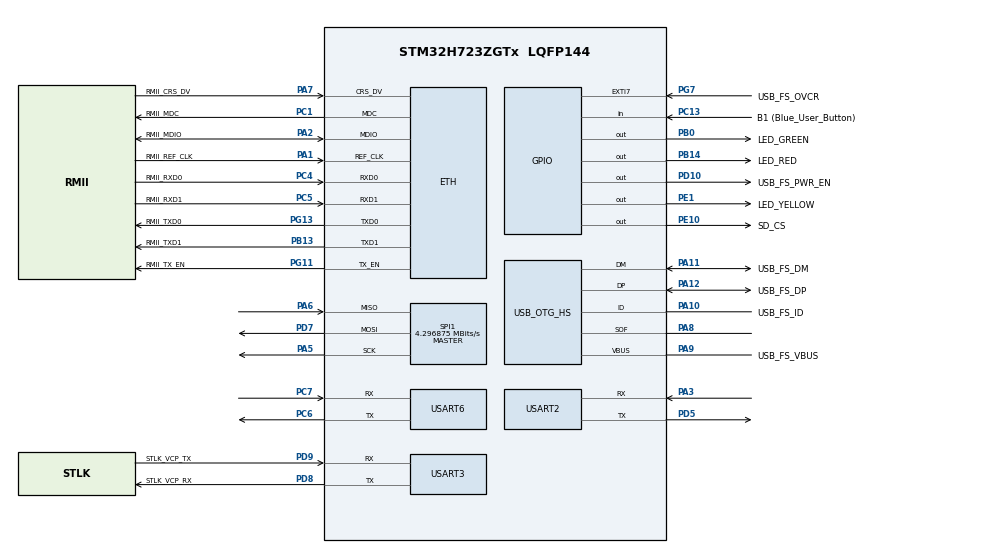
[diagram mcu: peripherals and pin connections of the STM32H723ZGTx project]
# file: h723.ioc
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Dma.Request0=USART3_RX
Dma.Request1=USART2_RX
Dma.USART2_RX.1.Direction=DMA_PERIPH_TO_MEMORY
Dma.USART2_RX.1.EventEnable=DISABLE
Dma.USART2_RX.1.FIFOMode=DMA_FIFOMODE_DISABLE
Dma.USART2_RX.1.Instance=DMA1_Stream1
Dma.USART2_RX.1.MemDataAlignment=DMA_MDATAALIGN_BYTE
Dma.USART2_RX.1.MemInc=DMA_MINC_ENABLE
Dma.USART2_RX.1.Mode=DMA_CIRCULAR
Dma.USART2_RX.1.PeriphDataAlignment=DMA_PDATAALIGN_BYTE
Dma.USART2_RX.1.PeriphInc=DMA_PINC_DISABLE
Dma.USART2_RX.1.Polarity=HAL_DMAMUX_REQ_GEN_RISING
Dma.USART2_RX.1.Priority=DMA_PRIORITY_LOW
Dma.USART2_RX.1.RequestNumber=1
Dma.USART2_RX.1.SignalID=NONE
Dma.USART2_RX.1.SyncEnable=DISABLE
Dma.USART2_RX.1.SyncPolarity=HAL_DMAMUX_SYNC_NO_EVENT
Dma.USART2_RX.1.SyncRequestNumber=1
Dma.USART2_RX.1.SyncSignalID=NONE
Dma.USART3_RX.0.Direction=DMA_PERIPH_TO_MEMORY
Dma.USART3_RX.0.EventEnable=DISABLE
Dma.USART3_RX.0.FIFOMode=DMA_FIFOMODE_DISABLE
Dma.USART3_RX.0.Instance=DMA1_Stream0
Dma.USART3_RX.0.MemDataAlignment=DMA_MDATAALIGN_BYTE
Dma.USART3_RX.0.MemInc=DMA_MINC_ENABLE
Dma.USART3_RX.0.Mode=DMA_CIRCULAR
Dma.USART3_RX.0.PeriphDataAlignment=DMA_PDATAALIGN_BYTE
Dma.USART3_RX.0.PeriphInc=DMA_PINC_DISABLE
Dma.USART3_RX.0.Polarity=HAL_DMAMUX_REQ_GEN_RISING
Dma.USART3_RX.0.Priority=DMA_PRIORITY_LOW
Dma.USART3_RX.0.RequestNumber=1
Dma.USART3_RX.0.SignalID=NONE
Dma.USART3_RX.0.SyncEnable=DISABLE
Dma.USART3_RX.0.SyncPolarity=HAL_DMAMUX_SYNC_NO_EVENT
Dma.USART3_RX.0.SyncRequestNumber=1
Dma.USART3_RX.0.SyncSignalID=NONE
ETH.MediaInterface=HAL_ETH_RMII_MODE
FATFS._MAX_SS=4096
FATFS._USE_LFN=1
Mcu.Family=STM32H7
Mcu.Name=STM32H723ZGTx
Mcu.Package=LQFP144
NVIC.DMA1_Stream0_IRQn=true\:0\:0\:false\:false\:true\:false\:true\:true
NVIC.DMA1_Stream1_IRQn=true\:0\:0\:false\:false\:true\:false\:true\:true
NVIC.PriorityGroup=NVIC_PRIORITYGROUP_4
NVIC.TIM1_UP_IRQn=true\:15\:0\:false\:false\:true\:false\:true\:true
NVIC.TimeBase=TIM1_UP_IRQn
NVIC.TimeBaseIP=TIM1
NVIC.USART2_IRQn=true\:5\:0\:true\:false\:true\:true\:true\:true
NVIC.USART3_IRQn=true\:5\:0\:true\:false\:true\:true\:true\:true
NVIC.USART6_IRQn=true\:5\:0\:true\:false\:true\:true\:true\:true
PA1.GPIO_Label=RMII_REF_CLK
PA1.Mode=RMII
PA1.Signal=ETH_REF_CLK
PA10.GPIO_Label=USB_FS_ID
PA10.Mode=OTG/Dual-Role-Device-FS
PA10.Signal=USB_OTG_HS_ID
PA11.GPIO_Label=USB_FS_DM
PA11.Mode=OTG/Dual-Role-Device-FS
PA11.Signal=USB_OTG_HS_DM
PA12.GPIO_Label=USB_FS_DP
PA12.Mode=OTG/Dual-Role-Device-FS
PA12.Signal=USB_OTG_HS_DP
PA13(JTMS/SWDIO).GPIO_Label=SWDIO
PA13(JTMS/SWDIO).Mode=Trace_Asynchronous_SW
PA13(JTMS/SWDIO).Signal=DEBUG_JTMS-SWDIO
PA14(JTCK/SWCLK).GPIO_Label=SWCLK
PA14(JTCK/SWCLK).Mode=Trace_Asynchronous_SW
PA14(JTCK/SWCLK).Signal=DEBUG_JTCK-SWCLK
PA2.GPIO_Label=RMII_MDIO
PA2.Mode=RMII
PA2.Signal=ETH_MDIO
PA3.Mode=Asynchronous
PA3.Signal=USART2_RX
PA5.Mode=Full_Duplex_Master
PA5.Signal=SPI1_SCK
PA6.Mode=Full_Duplex_Master
PA6.Signal=SPI1_MISO
PA7.GPIO_Label=RMII_CRS_DV
PA7.Mode=RMII
PA7.Signal=ETH_CRS_DV
PA8.Mode=Activate_SOF_FS
PA8.Signal=USB_OTG_HS_SOF
PA9.GPIO_Label=USB_FS_VBUS
PA9.Mode=Activate_VBUS_FS
PA9.Signal=USB_OTG_HS_VBUS
PB0.GPIO_Label=LED_GREEN
PB0.Signal=GPIO_Output
PB13.GPIO_Label=RMII_TXD1
PB13.Mode=RMII
PB13.Signal=ETH_TXD1
PB14.GPIO_Label=LED_RED
PB14.Signal=GPIO_Output
PB3(JTDO/TRACESWO).GPIO_Label=SWO
PB3(JTDO/TRACESWO).Mode=Trace_Asynchronous_SW
PB3(JTDO/TRACESWO).Signal=DEBUG_JTDO-SWO
PC1.GPIO_Label=RMII_MDC
PC1.Mode=RMII
PC1.Signal=ETH_MDC
PC13.GPIO_Label=B1 (Blue_User_Button)
PC13.Signal=GPIO_Input
PC14-OSC32_IN.Mode=LSE-External-Oscillator
PC14-OSC32_IN.Signal=RCC_OSC32_IN
PC15-OSC32_OUT.Mode=LSE-External-Oscillator
PC15-OSC32_OUT.Signal=RCC_OSC32_OUT
PC4.GPIO_Label=RMII_RXD0
PC4.Mode=RMII
PC4.Signal=ETH_RXD0
PC5.GPIO_Label=RMII_RXD1
PC5.Mode=RMII
PC5.Signal=ETH_RXD1
PC6.Mode=Asynchronous
PC6.Signal=USART6_TX
PC7.Mode=Asynchronous
PC7.Signal=USART6_RX
PD10.GPIO_Label=USB_FS_PWR_EN
PD10.Signal=GPIO_Output
PD5.Mode=Asynchronous
PD5.Signal=USART2_TX
PD7.Mode=Full_Duplex_Master
PD7.Signal=SPI1_MOSI
PD8.GPIO_Label=STLK_VCP_RX
PD8.Mode=Asynchronous
PD8.Signal=USART3_TX
PD9.GPIO_Label=STLK_VCP_TX
PD9.Mode=Asynchronous
PD9.Signal=USART3_RX
PE1.GPIO_Label=LED_YELLOW
PE1.Signal=GPIO_Output
PE10.GPIO_Label=SD_CS
PE10.PinState=GPIO_PIN_SET
PE10.Signal=GPIO_Output
PG11.GPIO_Label=RMII_TX_EN
PG11.Mode=RMII
PG11.Signal=ETH_TX_EN
PG13.GPIO_Label=RMII_TXD0
PG13.Mode=RMII
PG13.Signal=ETH_TXD0
PG7.GPIO_Label=USB_FS_OVCR
PG7.Signal=GPXTI7
PH0-OSC_IN.GPIO_Label=MCO
PH0-OSC_IN.Mode=HSE-External-Clock-Source
PH0-OSC_IN.Signal=RCC_OSC_IN
PH1-OSC_OUT.Signal=RCC_OSC_OUT
ProjectManager.HeapSize=0x200
ProjectManager.StackSize=0x400
ProjectManager.TargetToolchain=Makefile
RCC.ADCFreq_Value=76000000
RCC.APB1Freq_Value=137500000
RCC.APB2Freq_Value=137500000
RCC.APB3Freq_Value=137500000
RCC.APB4Freq_Value=137500000
RCC.CortexFreq_Value=550000000
RCC.D1PPRE=RCC_APB3_DIV2
RCC.D2PPRE1=RCC_APB1_DIV2
RCC.D2PPRE2=RCC_APB2_DIV2
RCC.D3PPRE=RCC_APB4_DIV2
RCC.DIVM1=4
RCC.DIVM2=1
RCC.DIVN1=275
RCC.DIVN2=19
RCC.DIVP1=1
RCC.DIVQ1=4
RCC.HCLKFreq_Value=275000000
RCC.HPRE=RCC_HCLK_DIV2
RCC.HSE_VALUE=8000000
RCC.PLLFRACN=0
RCC.PLLSourceVirtual=RCC_PLLSOURCE_HSE
RCC.SYSCLKFreq_VALUE=550000000
RCC.SYSCLKSource=RCC_SYSCLKSOURCE_PLLCLK
RCC.USBCLockSelection=RCC_USBCLKSOURCE_HSI48
RCC.USBFreq_Value=48000000
SPI1.BaudRatePrescaler=SPI_BAUDRATEPRESCALER_32
SPI1.CalculateBaudRate=4.296875 MBits/s
SPI1.DataSize=SPI_DATASIZE_8BIT
SPI1.Direction=SPI_DIRECTION_2LINES
SPI1.Mode=SPI_MODE_MASTER
SPI1.VirtualType=VM_MASTER
USART2.VirtualMode-Asynchronous=VM_ASYNC
USART3.VirtualMode-Asynchronous=VM_ASYNC
USART6.VirtualMode-Asynchronous=VM_ASYNC
VP_FATFS_VS_Generic.Mode=User_defined
VP_MEMORYMAP_VS_MEMORYMAP.Mode=CurAppReg
VP_SYS_VS_tim1.Mode=TIM1
board=NUCLEO-H723ZG

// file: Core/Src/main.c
/* USER CODE BEGIN Header */
/**
  ******************************************************************************
  * @file           : main.c
  * @brief          : Main program body
  ******************************************************************************
  * @attention
  *
  * Copyright (c) 2024 STMicroelectronics.
  * All rights reserved.
  *
  * This software is licensed under terms that can be found in the LICENSE file
  * in the root directory of this software component.
  * If no LICENSE file comes with this software, it is provided AS-IS.
  *
  ******************************************************************************
  */
/* USER CODE END Header */
#include "main.h"
#include "string.h"
#include "fatfs.h"

/* USER CODE BEGIN Includes */
#include "port_layer.h"
/* USER CODE END Includes */

#if defined ( __ICCARM__ ) /*!< IAR Compiler */
#pragma location=0x30000000
ETH_DMADescTypeDef  DMARxDscrTab[ETH_RX_DESC_CNT]; /* Ethernet Rx DMA Descriptors */
#pragma location=0x30000080
ETH_DMADescTypeDef  DMATxDscrTab[ETH_TX_DESC_CNT]; /* Ethernet Tx DMA Descriptors */

#elif defined ( __CC_ARM )  /* MDK ARM Compiler */

__attribute__((at(0x30000000))) ETH_DMADescTypeDef  DMARxDscrTab[ETH_RX_DESC_CNT]; /* Ethernet Rx DMA Descriptors */
__attribute__((at(0x30000080))) ETH_DMADescTypeDef  DMATxDscrTab[ETH_TX_DESC_CNT]; /* Ethernet Tx DMA Descriptors */

#elif defined ( __GNUC__ ) /* GNU Compiler */

ETH_DMADescTypeDef DMARxDscrTab[ETH_RX_DESC_CNT] __attribute__((section(".RxDecripSection"))); /* Ethernet Rx DMA Descriptors */
ETH_DMADescTypeDef DMATxDscrTab[ETH_TX_DESC_CNT] __attribute__((section(".TxDecripSection")));   /* Ethernet Tx DMA Descriptors */
#endif

ETH_TxPacketConfig TxConfig;

ETH_HandleTypeDef heth;

SPI_HandleTypeDef hspi1;

UART_HandleTypeDef huart2;
UART_HandleTypeDef huart3;
UART_HandleTypeDef huart6;
DMA_HandleTypeDef hdma_usart2_rx;
DMA_HandleTypeDef hdma_usart3_rx;

void SystemClock_Config(void);
static void MX_GPIO_Init(void);
static void MX_DMA_Init(void);
static void MX_ETH_Init(void);
static void MX_USART3_UART_Init(void);
static void MX_USB_OTG_HS_USB_Init(void);
static void MX_USART2_UART_Init(void);
static void MX_USART6_UART_Init(void);
static void MX_SPI1_Init(void);

int main(void)
{

  /* MCU Configuration--------------------------------------------------------*/

  /* Reset of all peripherals, Initializes the Flash interface and the Systick. */
  HAL_Init();

  /* Configure the system clock */
  SystemClock_Config();

  /* Initialize all configured peripherals */
  MX_GPIO_Init();
  MX_DMA_Init();
  MX_ETH_Init();
  MX_USART3_UART_Init();
  MX_USB_OTG_HS_USB_Init();
  MX_FATFS_Init();
  MX_USART2_UART_Init();
  MX_USART6_UART_Init();
  MX_SPI1_Init();
  /* USER CODE BEGIN 2 */
  //port_init();
  //port_start();
  /* USER CODE END 2 */

  /* Infinite loop */
  while (1)
  {

  }
}

void SystemClock_Config(void)
{
  RCC_OscInitTypeDef RCC_OscInitStruct = {0};
  RCC_ClkInitTypeDef RCC_ClkInitStruct = {0};

  /** Supply configuration update enable
  */
  HAL_PWREx_ConfigSupply(PWR_LDO_SUPPLY);

  /** Configure the main internal regulator output voltage
  */
  __HAL_PWR_VOLTAGESCALING_CONFIG(PWR_REGULATOR_VOLTAGE_SCALE0);

  while(!__HAL_PWR_GET_FLAG(PWR_FLAG_VOSRDY)) {}

  /** Initializes the RCC Oscillators according to the specified parameters
  * in the RCC_OscInitTypeDef structure.
  */
  RCC_OscInitStruct.OscillatorType = RCC_OSCILLATORTYPE_HSI48|RCC_OSCILLATORTYPE_HSE;
  RCC_OscInitStruct.HSEState = RCC_HSE_BYPASS;
  RCC_OscInitStruct.HSI48State = RCC_HSI48_ON;
  RCC_OscInitStruct.PLL.PLLState = RCC_PLL_ON;
  RCC_OscInitStruct.PLL.PLLSource = RCC_PLLSOURCE_HSE;
  RCC_OscInitStruct.PLL.PLLM = 4;
  RCC_OscInitStruct.PLL.PLLN = 275;
  RCC_OscInitStruct.PLL.PLLP = 1;
  RCC_OscInitStruct.PLL.PLLQ = 4;
  RCC_OscInitStruct.PLL.PLLR = 2;
  RCC_OscInitStruct.PLL.PLLRGE = RCC_PLL1VCIRANGE_1;
  RCC_OscInitStruct.PLL.PLLVCOSEL = RCC_PLL1VCOWIDE;
  RCC_OscInitStruct.PLL.PLLFRACN = 0;
  if (HAL_RCC_OscConfig(&RCC_OscInitStruct) != HAL_OK)
  {
    Error_Handler();
  }

  /** Initializes the CPU, AHB and APB buses clocks
  */
  RCC_ClkInitStruct.ClockType = RCC_CLOCKTYPE_HCLK|RCC_CLOCKTYPE_SYSCLK
                              |RCC_CLOCKTYPE_PCLK1|RCC_CLOCKTYPE_PCLK2
                              |RCC_CLOCKTYPE_D3PCLK1|RCC_CLOCKTYPE_D1PCLK1;
  RCC_ClkInitStruct.SYSCLKSource = RCC_SYSCLKSOURCE_PLLCLK;
  RCC_ClkInitStruct.SYSCLKDivider = RCC_SYSCLK_DIV1;
  RCC_ClkInitStruct.AHBCLKDivider = RCC_HCLK_DIV2;
  RCC_ClkInitStruct.APB3CLKDivider = RCC_APB3_DIV2;
  RCC_ClkInitStruct.APB1CLKDivider = RCC_APB1_DIV2;
  RCC_ClkInitStruct.APB2CLKDivider = RCC_APB2_DIV2;
  RCC_ClkInitStruct.APB4CLKDivider = RCC_APB4_DIV2;

  if (HAL_RCC_ClockConfig(&RCC_ClkInitStruct, FLASH_LATENCY_3) != HAL_OK)
  {
    Error_Handler();
  }
}

static void MX_ETH_Init(void)
{

   static uint8_t MACAddr[6];

  heth.Instance = ETH;
  MACAddr[0] = 0x00;
  MACAddr[1] = 0x80;
  MACAddr[2] = 0xE1;
  MACAddr[3] = 0x00;
  MACAddr[4] = 0x00;
  MACAddr[5] = 0x00;
  heth.Init.MACAddr = &MACAddr[0];
  heth.Init.MediaInterface = HAL_ETH_RMII_MODE;
  heth.Init.TxDesc = DMATxDscrTab;
  heth.Init.RxDesc = DMARxDscrTab;
  heth.Init.RxBuffLen = 1524;

  if (HAL_ETH_Init(&heth) != HAL_OK)
  {
    Error_Handler();
  }

  memset(&TxConfig, 0 , sizeof(ETH_TxPacketConfig));
  TxConfig.Attributes = ETH_TX_PACKETS_FEATURES_CSUM | ETH_TX_PACKETS_FEATURES_CRCPAD;
  TxConfig.ChecksumCtrl = ETH_CHECKSUM_IPHDR_PAYLOAD_INSERT_PHDR_CALC;
  TxConfig.CRCPadCtrl = ETH_CRC_PAD_INSERT;

}

static void MX_SPI1_Init(void)
{

  /* SPI1 parameter configuration*/
  hspi1.Instance = SPI1;
  hspi1.Init.Mode = SPI_MODE_MASTER;
  hspi1.Init.Direction = SPI_DIRECTION_2LINES;
  hspi1.Init.DataSize = SPI_DATASIZE_8BIT;
  hspi1.Init.CLKPolarity = SPI_POLARITY_LOW;
  hspi1.Init.CLKPhase = SPI_PHASE_1EDGE;
  hspi1.Init.NSS = SPI_NSS_SOFT;
  hspi1.Init.BaudRatePrescaler = SPI_BAUDRATEPRESCALER_32;
  hspi1.Init.FirstBit = SPI_FIRSTBIT_MSB;
  hspi1.Init.TIMode = SPI_TIMODE_DISABLE;
  hspi1.Init.CRCCalculation = SPI_CRCCALCULATION_DISABLE;
  hspi1.Init.CRCPolynomial = 0x0;
  hspi1.Init.NSSPMode = SPI_NSS_PULSE_ENABLE;
  hspi1.Init.NSSPolarity = SPI_NSS_POLARITY_LOW;
  hspi1.Init.FifoThreshold = SPI_FIFO_THRESHOLD_01DATA;
  hspi1.Init.TxCRCInitializationPattern = SPI_CRC_INITIALIZATION_ALL_ZERO_PATTERN;
  hspi1.Init.RxCRCInitializationPattern = SPI_CRC_INITIALIZATION_ALL_ZERO_PATTERN;
  hspi1.Init.MasterSSIdleness = SPI_MASTER_SS_IDLENESS_00CYCLE;
  hspi1.Init.MasterInterDataIdleness = SPI_MASTER_INTERDATA_IDLENESS_00CYCLE;
  hspi1.Init.MasterReceiverAutoSusp = SPI_MASTER_RX_AUTOSUSP_DISABLE;
  hspi1.Init.MasterKeepIOState = SPI_MASTER_KEEP_IO_STATE_DISABLE;
  hspi1.Init.IOSwap = SPI_IO_SWAP_DISABLE;
  if (HAL_SPI_Init(&hspi1) != HAL_OK)
  {
    Error_Handler();
  }

}

static void MX_USART2_UART_Init(void)
{

  huart2.Instance = USART2;
  huart2.Init.BaudRate = 115200;
  huart2.Init.WordLength = UART_WORDLENGTH_8B;
  huart2.Init.StopBits = UART_STOPBITS_1;
  huart2.Init.Parity = UART_PARITY_NONE;
  huart2.Init.Mode = UART_MODE_TX_RX;
  huart2.Init.HwFlowCtl = UART_HWCONTROL_NONE;
  huart2.Init.OverSampling = UART_OVERSAMPLING_16;
  huart2.Init.OneBitSampling = UART_ONE_BIT_SAMPLE_DISABLE;
  huart2.Init.ClockPrescaler = UART_PRESCALER_DIV1;
  huart2.AdvancedInit.AdvFeatureInit = UART_ADVFEATURE_NO_INIT;
  if (HAL_UART_Init(&huart2) != HAL_OK)
  {
    Error_Handler();
  }
  if (HAL_UARTEx_SetTxFifoThreshold(&huart2, UART_TXFIFO_THRESHOLD_1_8) != HAL_OK)
  {
    Error_Handler();
  }
  if (HAL_UARTEx_SetRxFifoThreshold(&huart2, UART_RXFIFO_THRESHOLD_1_8) != HAL_OK)
  {
    Error_Handler();
  }
  if (HAL_UARTEx_DisableFifoMode(&huart2) != HAL_OK)
  {
    Error_Handler();
  }

}

static void MX_USART3_UART_Init(void)
{

  huart3.Instance = USART3;
  huart3.Init.BaudRate = 115200;
  huart3.Init.WordLength = UART_WORDLENGTH_8B;
  huart3.Init.StopBits = UART_STOPBITS_1;
  huart3.Init.Parity = UART_PARITY_NONE;
  huart3.Init.Mode = UART_MODE_TX_RX;
  huart3.Init.HwFlowCtl = UART_HWCONTROL_NONE;
  huart3.Init.OverSampling = UART_OVERSAMPLING_16;
  huart3.Init.OneBitSampling = UART_ONE_BIT_SAMPLE_DISABLE;
  huart3.Init.ClockPrescaler = UART_PRESCALER_DIV1;
  huart3.AdvancedInit.AdvFeatureInit = UART_ADVFEATURE_NO_INIT;
  if (HAL_UART_Init(&huart3) != HAL_OK)
  {
    Error_Handler();
  }
  if (HAL_UARTEx_SetTxFifoThreshold(&huart3, UART_TXFIFO_THRESHOLD_1_8) != HAL_OK)
  {
    Error_Handler();
  }
  if (HAL_UARTEx_SetRxFifoThreshold(&huart3, UART_RXFIFO_THRESHOLD_1_8) != HAL_OK)
  {
    Error_Handler();
  }
  if (HAL_UARTEx_DisableFifoMode(&huart3) != HAL_OK)
  {
    Error_Handler();
  }

}

static void MX_USART6_UART_Init(void)
{

  huart6.Instance = USART6;
  huart6.Init.BaudRate = 115200;
  huart6.Init.WordLength = UART_WORDLENGTH_8B;
  huart6.Init.StopBits = UART_STOPBITS_1;
  huart6.Init.Parity = UART_PARITY_NONE;
  huart6.Init.Mode = UART_MODE_TX_RX;
  huart6.Init.HwFlowCtl = UART_HWCONTROL_NONE;
  huart6.Init.OverSampling = UART_OVERSAMPLING_16;
  huart6.Init.OneBitSampling = UART_ONE_BIT_SAMPLE_DISABLE;
  huart6.Init.ClockPrescaler = UART_PRESCALER_DIV1;
  huart6.AdvancedInit.AdvFeatureInit = UART_ADVFEATURE_NO_INIT;
  if (HAL_UART_Init(&huart6) != HAL_OK)
  {
    Error_Handler();
  }
  if (HAL_UARTEx_SetTxFifoThreshold(&huart6, UART_TXFIFO_THRESHOLD_1_8) != HAL_OK)
  {
    Error_Handler();
  }
  if (HAL_UARTEx_SetRxFifoThreshold(&huart6, UART_RXFIFO_THRESHOLD_1_8) != HAL_OK)
  {
    Error_Handler();
  }
  if (HAL_UARTEx_DisableFifoMode(&huart6) != HAL_OK)
  {
    Error_Handler();
  }

}

static void MX_USB_OTG_HS_USB_Init(void)
{

}

static void MX_DMA_Init(void)
{

  /* DMA controller clock enable */
  __HAL_RCC_DMA1_CLK_ENABLE();

  /* DMA interrupt init */
  /* DMA1_Stream0_IRQn interrupt configuration */
  HAL_NVIC_SetPriority(DMA1_Stream0_IRQn, 0, 0);
  HAL_NVIC_EnableIRQ(DMA1_Stream0_IRQn);
  /* DMA1_Stream1_IRQn interrupt configuration */
  HAL_NVIC_SetPriority(DMA1_Stream1_IRQn, 0, 0);
  HAL_NVIC_EnableIRQ(DMA1_Stream1_IRQn);

}

static void MX_GPIO_Init(void)
{
  GPIO_InitTypeDef GPIO_InitStruct = {0};

  /* GPIO Ports Clock Enable */
  __HAL_RCC_GPIOC_CLK_ENABLE();
  __HAL_RCC_GPIOH_CLK_ENABLE();
  __HAL_RCC_GPIOA_CLK_ENABLE();
  __HAL_RCC_GPIOB_CLK_ENABLE();
  __HAL_RCC_GPIOE_CLK_ENABLE();
  __HAL_RCC_GPIOD_CLK_ENABLE();
  __HAL_RCC_GPIOG_CLK_ENABLE();

  /*Configure GPIO pin Output Level */
  HAL_GPIO_WritePin(GPIOB, LED_GREEN_Pin|LED_RED_Pin, GPIO_PIN_RESET);

  /*Configure GPIO pin Output Level */
  HAL_GPIO_WritePin(SD_CS_GPIO_Port, SD_CS_Pin, GPIO_PIN_SET);

  /*Configure GPIO pin Output Level */
  HAL_GPIO_WritePin(USB_FS_PWR_EN_GPIO_Port, USB_FS_PWR_EN_Pin, GPIO_PIN_RESET);

  /*Configure GPIO pin Output Level */
  HAL_GPIO_WritePin(LED_YELLOW_GPIO_Port, LED_YELLOW_Pin, GPIO_PIN_RESET);

  /*Configure GPIO pin : B1_Pin */
  GPIO_InitStruct.Pin = B1_Pin;
  GPIO_InitStruct.Mode = GPIO_MODE_INPUT;
  GPIO_InitStruct.Pull = GPIO_NOPULL;
  HAL_GPIO_Init(B1_GPIO_Port, &GPIO_InitStruct);

  /*Configure GPIO pins : LED_GREEN_Pin LED_RED_Pin */
  GPIO_InitStruct.Pin = LED_GREEN_Pin|LED_RED_Pin;
  GPIO_InitStruct.Mode = GPIO_MODE_OUTPUT_PP;
  GPIO_InitStruct.Pull = GPIO_NOPULL;
  GPIO_InitStruct.Speed = GPIO_SPEED_FREQ_LOW;
  HAL_GPIO_Init(GPIOB, &GPIO_InitStruct);

  /*Configure GPIO pins : SD_CS_Pin LED_YELLOW_Pin */
  GPIO_InitStruct.Pin = SD_CS_Pin|LED_YELLOW_Pin;
  GPIO_InitStruct.Mode = GPIO_MODE_OUTPUT_PP;
  GPIO_InitStruct.Pull = GPIO_NOPULL;
  GPIO_InitStruct.Speed = GPIO_SPEED_FREQ_LOW;
  HAL_GPIO_Init(GPIOE, &GPIO_InitStruct);

  /*Configure GPIO pin : USB_FS_PWR_EN_Pin */
  GPIO_InitStruct.Pin = USB_FS_PWR_EN_Pin;
  GPIO_InitStruct.Mode = GPIO_MODE_OUTPUT_PP;
  GPIO_InitStruct.Pull = GPIO_NOPULL;
  GPIO_InitStruct.Speed = GPIO_SPEED_FREQ_LOW;
  HAL_GPIO_Init(USB_FS_PWR_EN_GPIO_Port, &GPIO_InitStruct);

  /*Configure GPIO pin : USB_FS_OVCR_Pin */
  GPIO_InitStruct.Pin = USB_FS_OVCR_Pin;
  GPIO_InitStruct.Mode = GPIO_MODE_IT_RISING;
  GPIO_InitStruct.Pull = GPIO_NOPULL;
  HAL_GPIO_Init(USB_FS_OVCR_GPIO_Port, &GPIO_InitStruct);

  /*Configure GPIO pins : PA8 USB_FS_ID_Pin */
  GPIO_InitStruct.Pin = GPIO_PIN_8|USB_FS_ID_Pin;
  GPIO_InitStruct.Mode = GPIO_MODE_AF_PP;
  GPIO_InitStruct.Pull = GPIO_NOPULL;
  GPIO_InitStruct.Speed = GPIO_SPEED_FREQ_LOW;
  GPIO_InitStruct.Alternate = GPIO_AF10_OTG1_HS;
  HAL_GPIO_Init(GPIOA, &GPIO_InitStruct);

  /*Configure GPIO pin : USB_FS_VBUS_Pin */
  GPIO_InitStruct.Pin = USB_FS_VBUS_Pin;
  GPIO_InitStruct.Mode = GPIO_MODE_INPUT;
  GPIO_InitStruct.Pull = GPIO_NOPULL;
  HAL_GPIO_Init(USB_FS_VBUS_GPIO_Port, &GPIO_InitStruct);

}

void HAL_TIM_PeriodElapsedCallback(TIM_HandleTypeDef *htim)
{
  if (htim->Instance == TIM1) {
    HAL_IncTick();
  }
}

void Error_Handler(void)
{
  __disable_irq();
  while (1)
  {
  }
}
